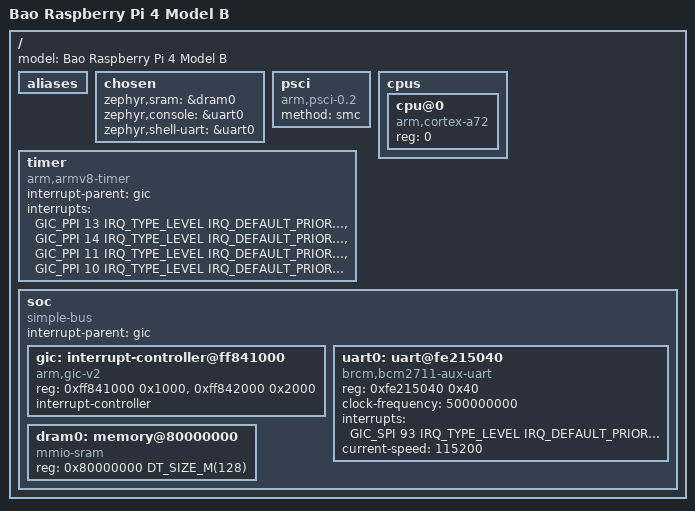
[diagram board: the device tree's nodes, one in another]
/*
 * Copyright (c) 2021 Carlo Caione <ccaione@baylibre.com>
 * Copyright (c) 2023 Yan-Jie Wang <yanjiewtw@gmail.com>
 * SPDX-License-Identifier: Apache-2.0
 */

/dts-v1/;

#include <mem.h>
#include <zephyr/dt-bindings/interrupt-controller/arm-gic.h>

/ {
	model = "Bao Raspberry Pi 4 Model B";

	#address-cells = <1>;
	#size-cells = <1>;

	aliases { };

	chosen {
		/*
		 * The SRAM node is actually located in the
		 * DRAM region of the FVP Base RevC 2xAEMv8A.
		 */
		zephyr,sram = &dram0;
		zephyr,console = &uart0;
		zephyr,shell-uart = &uart0;
	};

	psci {
		compatible = "arm,psci-0.2";
		method = "smc";
	};

	cpus {
		#address-cells = <1>;
		#size-cells = <0>;

		cpu@0 {
			device_type = "cpu";
			compatible = "arm,cortex-a72";
			reg = <0>;
		};
	};

	timer {
		compatible = "arm,armv8-timer";
		interrupt-parent = <&gic>;
		interrupts = <GIC_PPI 13 IRQ_TYPE_LEVEL
			      IRQ_DEFAULT_PRIORITY>,
			     <GIC_PPI 14 IRQ_TYPE_LEVEL
			      IRQ_DEFAULT_PRIORITY>,
			     <GIC_PPI 11 IRQ_TYPE_LEVEL
			      IRQ_DEFAULT_PRIORITY>,
			     <GIC_PPI 10 IRQ_TYPE_LEVEL
			      IRQ_DEFAULT_PRIORITY>;
	};

	soc {
		#address-cells = <1>;
		#size-cells = <1>;
		compatible = "simple-bus";
		ranges;
		interrupt-parent = <&gic>;

		gic: interrupt-controller@ff841000 {
			compatible = "arm,gic-v2", "arm,gic";
			reg = <0xff841000 0x1000>,
			      <0xff842000 0x2000>;
			interrupt-controller;
			#interrupt-cells = <4>;
			status = "okay";
			#address-cells = <1>;
			#size-cells = <1>;
		};

		uart0: uart@fe215040 {
			compatible = "brcm,bcm2711-aux-uart";
			reg = <0xfe215040 0x40>;
			clock-frequency = <500000000>;
			interrupts = <GIC_SPI 93 IRQ_TYPE_LEVEL IRQ_DEFAULT_PRIORITY>;
			status = "disabled";
		};

		dram0: memory@80000000 {
			compatible = "mmio-sram";
			reg = <0x80000000 DT_SIZE_M(128)>;
		};
	};
};

&uart0 {
	status = "okay";
	current-speed = <115200>;
};
